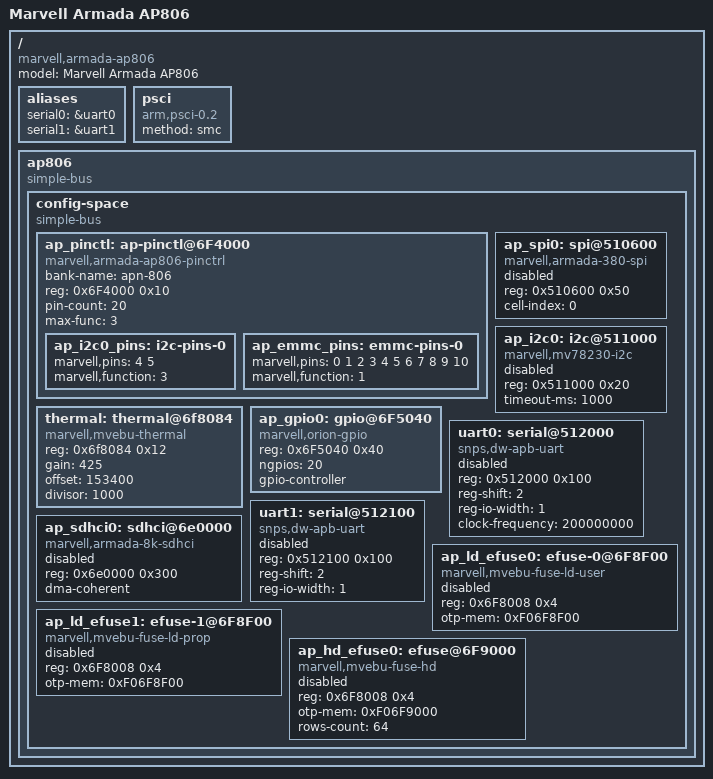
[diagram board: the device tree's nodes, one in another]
/*
 * Copyright (C) 2016 Marvell Technology Group Ltd.
 *
 * This file is dual-licensed: you can use it either under the terms
 * of the GPLv2 or the X11 license, at your option. Note that this dual
 * licensing only applies to this file, and not this project as a
 * whole.
 *
 *  a) This library is free software; you can redistribute it and/or
 *     modify it under the terms of the GNU General Public License as
 *     published by the Free Software Foundation; either version 2 of the
 *     License, or (at your option) any later version.
 *
 *     This library is distributed in the hope that it will be useful,
 *     but WITHOUT ANY WARRANTY; without even the implied warranty of
 *     MERCHANTABILITY or FITNESS FOR A PARTICULAR PURPOSE.  See the
 *     GNU General Public License for more details.
 *
 * Or, alternatively,
 *
 *  b) Permission is hereby granted, free of charge, to any person
 *     obtaining a copy of this software and associated documentation
 *     files (the "Software"), to deal in the Software without
 *     restriction, including without limitation the rights to use,
 *     copy, modify, merge, publish, distribute, sublicense, and/or
 *     sell copies of the Software, and to permit persons to whom the
 *     Software is furnished to do so, subject to the following
 *     conditions:
 *
 *     The above copyright notice and this permission notice shall be
 *     included in all copies or substantial portions of the Software.
 *
 *     THE SOFTWARE IS PROVIDED "AS IS", WITHOUT WARRANTY OF ANY KIND,
 *     EXPRESS OR IMPLIED, INCLUDING BUT NOT LIMITED TO THE WARRANTIES
 *     OF MERCHANTABILITY, FITNESS FOR A PARTICULAR PURPOSE AND
 *     NONINFRINGEMENT. IN NO EVENT SHALL THE AUTHORS OR COPYRIGHT
 *     HOLDERS BE LIABLE FOR ANY CLAIM, DAMAGES OR OTHER LIABILITY,
 *     WHETHER IN AN ACTION OF CONTRACT, TORT OR OTHERWISE, ARISING
 *     FROM, OUT OF OR IN CONNECTION WITH THE SOFTWARE OR THE USE OR
 *     OTHER DEALINGS IN THE SOFTWARE.
 */

/*
 * Device Tree file for Marvell Armada AP806.
 */

/dts-v1/;

/ {
	model = "Marvell Armada AP806";
	compatible = "marvell,armada-ap806";
	#address-cells = <2>;
	#size-cells = <2>;

	aliases {
		serial0 = &uart0;
		serial1 = &uart1;
	};

	psci {
		compatible = "arm,psci-0.2";
		method = "smc";
	};

	ap806 {
		#address-cells = <2>;
		#size-cells = <2>;
		compatible = "simple-bus";
		ranges;

		config-space {
			#address-cells = <1>;
			#size-cells = <1>;
			compatible = "simple-bus";
			ranges = <0x0 0x0 0xf0000000 0x1000000>;

			ap_pinctl: ap-pinctl@6F4000 {
				compatible = "marvell,armada-ap806-pinctrl";
				bank-name ="apn-806";
				reg = <0x6F4000 0x10>;
				pin-count = <20>;
				max-func = <3>;

				ap_i2c0_pins: i2c-pins-0 {
					marvell,pins = < 4 5 >;
					marvell,function = <3>;
				};
				ap_emmc_pins: emmc-pins-0 {
					marvell,pins = < 0 1 2 3 4 5 6 7
							 8 9 10 >;
					marvell,function = <1>;
				};
			};

			thermal: thermal@6f8084 {
				compatible = "marvell,mvebu-thermal", "marvell,thermal-ext-sensor";
				reg = <0x6f8084 0x12>;
				gain = <425>;
				offset = <153400>;
				divisor = <1000>;
				status = "okay";
			};

			ap_gpio0: gpio@6F5040 {
				compatible = "marvell,orion-gpio";
				reg = <0x6F5040 0x40>;
				ngpios = <20>;
				gpio-controller;
				#gpio-cells = <2>;
			};

			ap_spi0: spi@510600 {
				compatible = "marvell,armada-380-spi";
				reg = <0x510600 0x50>;
				#address-cells = <1>;
				#size-cells = <0>;
				cell-index = <0>;
				status = "disabled";
			};

			ap_i2c0: i2c@511000 {
				compatible = "marvell,mv78230-i2c";
				reg = <0x511000 0x20>;
				#address-cells = <1>;
				#size-cells = <0>;
				timeout-ms = <1000>;
				status = "disabled";
			};

			uart0: serial@512000 {
				compatible = "snps,dw-apb-uart";
				reg = <0x512000 0x100>;
				reg-shift = <2>;
				reg-io-width = <1>;
				status = "disabled";
				clock-frequency = <200000000>;
			};

			uart1: serial@512100 {
				compatible = "snps,dw-apb-uart";
				reg = <0x512100 0x100>;
				reg-shift = <2>;
				reg-io-width = <1>;
				status = "disabled";

			};

			ap_sdhci0: sdhci@6e0000 {
				compatible = "marvell,armada-8k-sdhci";
				reg = <0x6e0000 0x300>;
				dma-coherent;
				status = "disabled";
			};

			ap_ld_efuse0: efuse-0@6F8F00 {
				compatible = "marvell,mvebu-fuse-ld-user";
				reg = <0x6F8008 0x4>;
				otp-mem = <0xF06F8F00>;
				status = "disabled";
			};

			ap_ld_efuse1: efuse-1@6F8F00 {
				compatible = "marvell,mvebu-fuse-ld-prop";
				reg = <0x6F8008 0x4>;
				otp-mem = <0xF06F8F00>;
				status = "disabled";
			};

			ap_hd_efuse0: efuse@6F9000  {
				compatible = "marvell,mvebu-fuse-hd";
				reg = <0x6F8008 0x4>;
				otp-mem = <0xF06F9000>;
				rows-count = <64>;
				status = "disabled";
			};

		};
	};
};
